# RZN2H register map
Vendor: Renesas Electronics Corporation; Series: RZN; File version: 1.00.00
CPU: other r0p0, little endian, MPU, no FPU, VTOR, 4 interrupt priority bits, 624 interrupts
Registers are 32-bit, read-write, reset 0x0 unless marked. A register's access mark holds for its fields unless they carry their own. Offsets are from the block's base; [hi:lo] are bit positions; {n}, {i} and the like mark numbered series.

## CA55 — Cortex-A55
Base 0x81295020
{0x0+8i} RVBAL{i} (i=0..3) — CA55 Core {i} Reset Vector Address Low Configuration Register
  [31:2] RVBARADDRL — Cortex-A55 Core n Reset Vector Address Low
{0x4+8i} RVBAH{i} (i=0..3) — CA55 Core {i} Reset Vector Address High Configuration Register
  [7:0] RVBARADDRH — Cortex-A55 Core n Reset Vector Address High

## WDT_DBG — WDT for Debug
Base 0x81295100
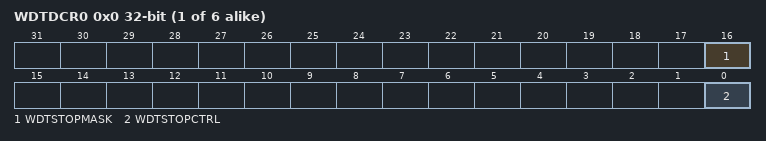
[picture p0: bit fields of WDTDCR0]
{0x0+4i} WDTDCR{i} (i=0..5) — WDT Debug Control Register {i}
  [16] WDTSTOPMASK
    0=haltdbg is not masked; 1=haltdbg is masked
  [0] WDTSTOPCTRL
    0=WDT count is enabled, and interrupt is enabled; 1=WDT count is stopped, and interrupt is disabled

## RWP_S — Register Write Protection for Safety Area
Base 0x81296000
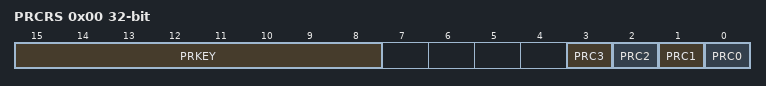
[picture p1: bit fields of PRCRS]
0x00 PRCRS — Safety Area Protect Register
  [15:8] PRKEY wo — PRC Key Code
  [n] PRC{n} (n=0..3) — Protect {n}
    0=Write disabled; 1=Write enabled

## ICU_S — Interrupt Controller in Safety Domain
Base 0x812A0000
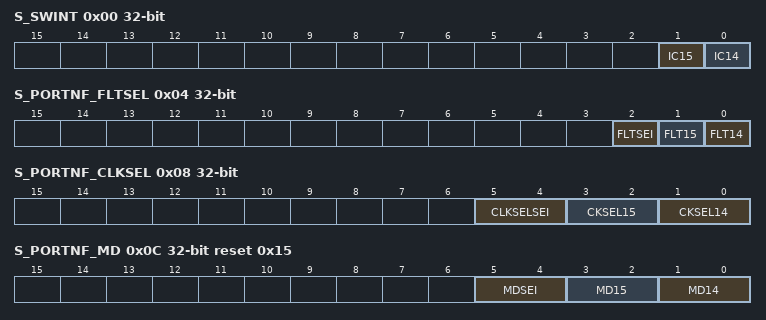
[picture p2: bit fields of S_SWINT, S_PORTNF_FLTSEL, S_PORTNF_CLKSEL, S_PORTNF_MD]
0x00 S_SWINT wo — Software Interrupt Register for Safety Register
  [1] IC15 — Software Interrupt register
  [0] IC14 — Software Interrupt register
0x04 S_PORTNF_FLTSEL — Interrupt Noise Filter Enable Register for Safety Register
  [all] fields
    0=Disable; 1=Enable
  [2] FLTSEI — Noise filter enable for SEI
  [1] FLT15 — Noise filter enable for IRQ15
  [0] FLT14 — Noise filter enable for IRQ14
0x08 S_PORTNF_CLKSEL — Interrupt Noise Filter Setting Register for Safety Register
  [all] fields
    0=Divided by 1; 1=Divided by 8; 2=Divided by 32; 3=Divided by 64
  [5:4] CLKSELSEI — Select noise filter sampling frequency dividend rate for SEI.
  [3:2] CKSEL15 — Select noise filter sampling frequency dividend rate for IRQ15.
  [1:0] CKSEL14 — Select noise filter sampling frequency dividend rate for IRQ14.
0x0C S_PORTNF_MD reset 0x15 — Interrupt Edge Detection Setting Register for Safety Register
  [all] fields
    0=Low level; 1=Falling edge; 2=Rising edge; 3=Falling and rising edges
  [5:4] MDSEI — Select detection mode for SEI
  [3:2] MD15 — Select detection mode for IRQ15
  [1:0] MD14 — Select detection mode for IRQ14
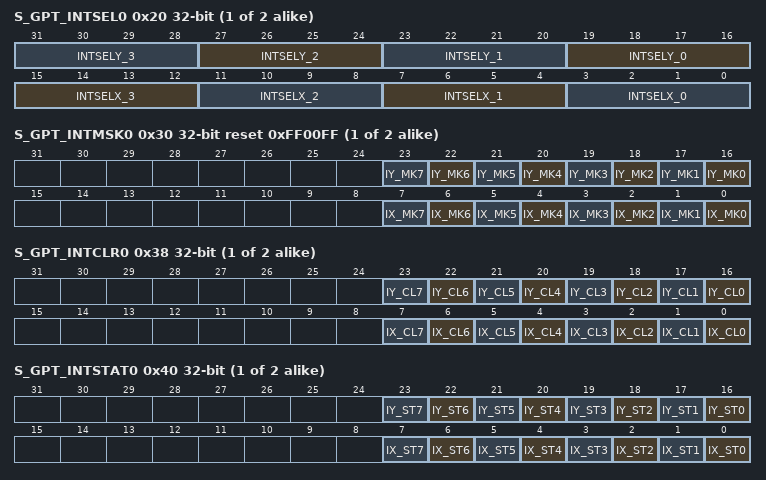
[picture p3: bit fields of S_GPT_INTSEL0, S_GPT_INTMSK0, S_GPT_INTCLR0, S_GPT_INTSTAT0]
{0x20+4i} S_GPT_INTSEL{i} (i=0..1) — Safety GPT Interrupt Select Register {i}
  [4n+19:4n+16] INTSELY_{n} (n=0..3) — Select GPT event source to be output as GPTy_INT{n} event
  [15:12] INTSELX_3 — Select GPT event source to be output as GPTx_INT3 event
  [11:8] INTSELX_2 — Select GPT event source to be output as GPTx_INT2 event
  [7:4] INTSELX_1 — Select GPT event source to be output as GPTx_INT1 event
  [3:0] INTSELX_0
{0x30+4i} S_GPT_INTMSK{i} (i=0..1) reset 0xFF00FF — Safety GPT Combined Interrupt Mask Register {i}
  [all] fields
    0=No masked; 1=Masked
  [n+16] IY_MK{n} (n=0..7)
  [n] IX_MK{n} (n=0..7)
{0x38+4i} S_GPT_INTCLR{i} (i=0..1) wo — Safety GPT Combined Interrupt Status Clear Register {i}
  [n+16] IY_CL{n} (n=0..7), [n] IX_CL{n} (n=0..7)
{0x40+4i} S_GPT_INTSTAT{i} (i=0..1) ro — Safety GPT Combined Interrupt Status Register {i}
  [all] fields
    0=No event occurs; 1=Event occurs
  [n+16] IY_ST{n} (n=0..7)
  [n] IX_ST{n} (n=0..7)

## GSC — Global System Counter
Base 0x8C200000
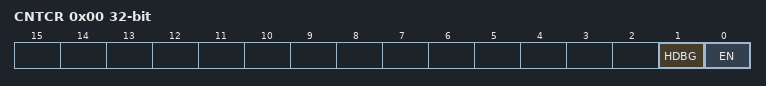
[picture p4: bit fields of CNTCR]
0x00 CNTCR — Global System Counter Control Register
  [1] HDBG — Halt on Debug
    0=Do not halt on debug, HLTDBG signal into the counter has no effect; 1=Halt on debug, when HLTDBG is driven high, the count value is held static
  [0] EN — Counter Enable
    0=The counter is disabled and not incrementing; 1=The counter is enabled and is incrementing
0x04 CNTSR ro — Global System Counter Status Register
  [1] DBGH — Debug Halted
    0=Not halt on debug; 1=Halt on debug
0x08 CNTCVL — Global System Counter Current Value Lower Register
  [31:0] CNTCVL_L_32 — Current value of the counter, lower 32 bits
0x0C CNTCVU — Global System Counter Current Value Upper Register
  [31:0] CNTCVU_U_32 — Current value of the counter, upper 32 bits
0x20 CNTFID0 — Global System Counter Base Frequency ID Register
  [31:0] FREQ — Frequency in number of ticks per second
